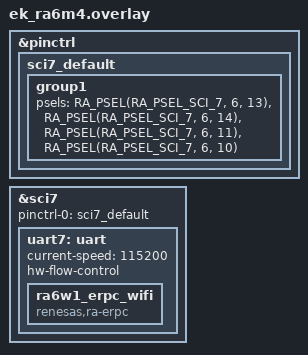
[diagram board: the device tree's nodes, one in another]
/*
 * Copyright (c) 2025 Renesas Electronics Corporation
 *
 * SPDX-License-Identifier: Apache-2.0
 */

&pinctrl {
	sci7_default: sci7_default {
		group1 {
			/* tx rx rts cts */
			psels = <RA_PSEL(RA_PSEL_SCI_7, 6, 13)>,
			<RA_PSEL(RA_PSEL_SCI_7, 6, 14)>,
			<RA_PSEL(RA_PSEL_SCI_7, 6, 11)>,
			<RA_PSEL(RA_PSEL_SCI_7, 6, 10)>;
		};
	};
};

&sci7 {
	pinctrl-0 = <&sci7_default>;
	pinctrl-names = "default";
	status = "okay";
	uart7: uart {
		current-speed = <115200>;
		hw-flow-control;
		status = "okay";

		ra6w1_erpc_wifi {
			compatible = "renesas,ra-erpc";
			status = "okay";
		};
	};
};
